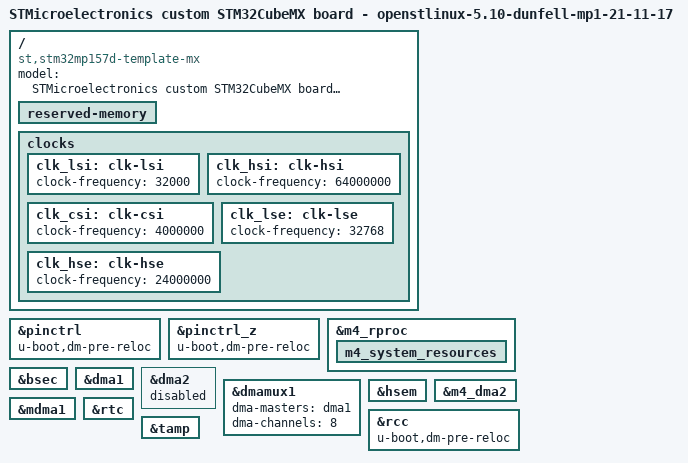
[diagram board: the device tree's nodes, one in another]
/* SPDX-License-Identifier: (GPL-2.0+ OR BSD-3-Clause) */
/*
 * Copyright (C) STMicroelectronics 2021 - All Rights Reserved
 * Author: STM32CubeMX code generation for STMicroelectronics.
 */

/* For more information on Device Tree configuration, please refer to
 * https://wiki.st.com/stm32mpu/wiki/Category:Device_tree_configuration
 */

/dts-v1/;
#include <dt-bindings/pinctrl/stm32-pinfunc.h>

#include "stm32mp157.dtsi"
#include "stm32mp15xd.dtsi"
#include "stm32mp15xxaa-pinctrl.dtsi"
#include "stm32mp15-m4-srm.dtsi"

/* USER CODE BEGIN includes */
/* USER CODE END includes */

/ {
	model = "STMicroelectronics custom STM32CubeMX board - openstlinux-5.10-dunfell-mp1-21-11-17";
	compatible = "st,stm32mp157d-template-mx", "st,stm32mp157";

	/* !!! log : Warning - no DDR config found: 'memory' node not generated  !!! */

	/*
	memory@??? {
		reg = < ??? >;
	};
	*/

	reserved-memory {
		#address-cells = <1>;
		#size-cells = <1>;
		ranges;

		/* USER CODE BEGIN reserved-memory */
		/* USER CODE END reserved-memory */
	};

	/* USER CODE BEGIN root */
	/* USER CODE END root */

	clocks {
		/* USER CODE BEGIN clocks */
		/* USER CODE END clocks */

#ifndef CONFIG_TFABOOT
		clk_lsi: clk-lsi {
			clock-frequency = <32000>;
		};
		clk_hsi: clk-hsi {
			clock-frequency = <64000000>;
		};
		clk_csi: clk-csi {
			clock-frequency = <4000000>;
		};
		clk_lse: clk-lse {
			clock-frequency = <32768>;
		};
		clk_hse: clk-hse {
			clock-frequency = <24000000>;
		};
#endif	/*CONFIG_TFABOOT*/
	};

}; /*root*/

&pinctrl {
	u-boot,dm-pre-reloc;

	/* USER CODE BEGIN pinctrl */
	/* USER CODE END pinctrl */
};

&pinctrl_z {
	u-boot,dm-pre-reloc;

	/* USER CODE BEGIN pinctrl_z */
	/* USER CODE END pinctrl_z */
};

&m4_rproc{
	status = "okay";

	/* USER CODE BEGIN m4_rproc */
	/* USER CODE END m4_rproc */

	m4_system_resources{
		status = "okay";

		/* USER CODE BEGIN m4_system_resources */
		/* USER CODE END m4_system_resources */
	};
};

&bsec{
	status = "okay";

	/* USER CODE BEGIN bsec */
	/* USER CODE END bsec */
};

&dma1{
	status = "okay";

	/* USER CODE BEGIN dma1 */
	/* USER CODE END dma1 */
};

&dma2{
	status = "disabled";

	/* USER CODE BEGIN dma2 */
	/* USER CODE END dma2 */
};

&dmamux1{
	status = "okay";

	dma-masters = <&dma1>;
	dma-channels = <8>;

	/* USER CODE BEGIN dmamux1 */
	/* USER CODE END dmamux1 */
};

&hsem{
	status = "okay";

	/* USER CODE BEGIN hsem */
	/* USER CODE END hsem */
};

&m4_dma2{
	status = "okay";

	/* USER CODE BEGIN m4_dma2 */
	/* USER CODE END m4_dma2 */
};

&mdma1{
	status = "okay";

	/* USER CODE BEGIN mdma1 */
	/* USER CODE END mdma1 */
};

&rcc{
	u-boot,dm-pre-reloc;
	status = "okay";

	/* USER CODE BEGIN rcc */
	/* USER CODE END rcc */
};

&rtc{
	status = "okay";

	/* USER CODE BEGIN rtc */
	/* USER CODE END rtc */
};

&tamp{
	status = "okay";

	/* USER CODE BEGIN tamp */
	/* USER CODE END tamp */
};

/* USER CODE BEGIN addons */
/* USER CODE END addons */

